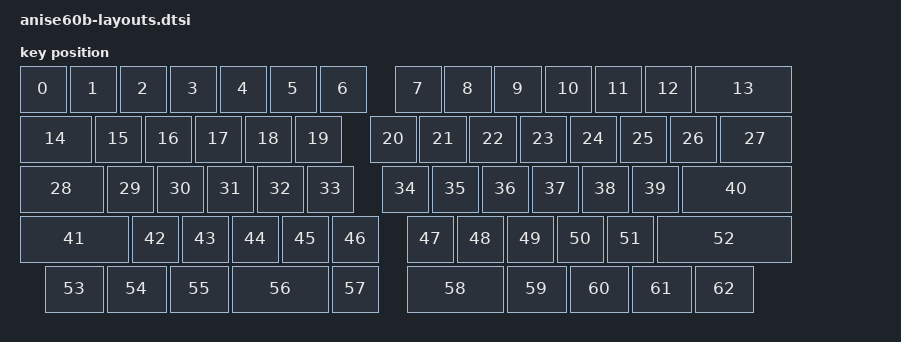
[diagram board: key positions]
#include <physical_layouts.dtsi>

/*
 * Generated by tools/make_layouts.py from anisehid/anise-kbd desc-gen/desc/anise60b.json.
 * Order matches default_transform in anise60b.dtsi.
 */

/ {
    anise60b_layout: anise60b_layout {
        compatible = "zmk,physical-layout";
        display-name = "Anise60B";

        keys  //                     w   h    x    y  rot  rx  ry
            = <&key_physical_attrs 100 100    0    0    0   0   0>
            , <&key_physical_attrs 100 100  100    0    0   0   0>
            , <&key_physical_attrs 100 100  200    0    0   0   0>
            , <&key_physical_attrs 100 100  300    0    0   0   0>
            , <&key_physical_attrs 100 100  400    0    0   0   0>
            , <&key_physical_attrs 100 100  500    0    0   0   0>
            , <&key_physical_attrs 100 100  600    0    0   0   0>
            , <&key_physical_attrs 100 100  750    0    0   0   0>
            , <&key_physical_attrs 100 100  850    0    0   0   0>
            , <&key_physical_attrs 100 100  950    0    0   0   0>
            , <&key_physical_attrs 100 100 1050    0    0   0   0>
            , <&key_physical_attrs 100 100 1150    0    0   0   0>
            , <&key_physical_attrs 100 100 1250    0    0   0   0>
            , <&key_physical_attrs 200 100 1350    0    0   0   0>
            , <&key_physical_attrs 150 100    0  100    0   0   0>
            , <&key_physical_attrs 100 100  150  100    0   0   0>
            , <&key_physical_attrs 100 100  250  100    0   0   0>
            , <&key_physical_attrs 100 100  350  100    0   0   0>
            , <&key_physical_attrs 100 100  450  100    0   0   0>
            , <&key_physical_attrs 100 100  550  100    0   0   0>
            , <&key_physical_attrs 100 100  700  100    0   0   0>
            , <&key_physical_attrs 100 100  800  100    0   0   0>
            , <&key_physical_attrs 100 100  900  100    0   0   0>
            , <&key_physical_attrs 100 100 1000  100    0   0   0>
            , <&key_physical_attrs 100 100 1100  100    0   0   0>
            , <&key_physical_attrs 100 100 1200  100    0   0   0>
            , <&key_physical_attrs 100 100 1300  100    0   0   0>
            , <&key_physical_attrs 150 100 1400  100    0   0   0>
            , <&key_physical_attrs 175 100    0  200    0   0   0>
            , <&key_physical_attrs 100 100  175  200    0   0   0>
            , <&key_physical_attrs 100 100  275  200    0   0   0>
            , <&key_physical_attrs 100 100  375  200    0   0   0>
            , <&key_physical_attrs 100 100  475  200    0   0   0>
            , <&key_physical_attrs 100 100  575  200    0   0   0>
            , <&key_physical_attrs 100 100  725  200    0   0   0>
            , <&key_physical_attrs 100 100  825  200    0   0   0>
            , <&key_physical_attrs 100 100  925  200    0   0   0>
            , <&key_physical_attrs 100 100 1025  200    0   0   0>
            , <&key_physical_attrs 100 100 1125  200    0   0   0>
            , <&key_physical_attrs 100 100 1225  200    0   0   0>
            , <&key_physical_attrs 225 100 1325  200    0   0   0>
            , <&key_physical_attrs 225 100    0  300    0   0   0>
            , <&key_physical_attrs 100 100  225  300    0   0   0>
            , <&key_physical_attrs 100 100  325  300    0   0   0>
            , <&key_physical_attrs 100 100  425  300    0   0   0>
            , <&key_physical_attrs 100 100  525  300    0   0   0>
            , <&key_physical_attrs 100 100  625  300    0   0   0>
            , <&key_physical_attrs 100 100  775  300    0   0   0>
            , <&key_physical_attrs 100 100  875  300    0   0   0>
            , <&key_physical_attrs 100 100  975  300    0   0   0>
            , <&key_physical_attrs 100 100 1075  300    0   0   0>
            , <&key_physical_attrs 100 100 1175  300    0   0   0>
            , <&key_physical_attrs 275 100 1275  300    0   0   0>
            , <&key_physical_attrs 125 100   50  400    0   0   0>
            , <&key_physical_attrs 125 100  175  400    0   0   0>
            , <&key_physical_attrs 125 100  300  400    0   0   0>
            , <&key_physical_attrs 200 100  425  400    0   0   0>
            , <&key_physical_attrs 100 100  625  400    0   0   0>
            , <&key_physical_attrs 200 100  775  400    0   0   0>
            , <&key_physical_attrs 125 100  975  400    0   0   0>
            , <&key_physical_attrs 125 100 1100  400    0   0   0>
            , <&key_physical_attrs 125 100 1225  400    0   0   0>
            , <&key_physical_attrs 125 100 1350  400    0   0   0>
            ;
    };
};
